# ESP32-P4 register map
Vendor: ESPRESSIF SYSTEMS (SHANGHAI) CO., LTD.; Series: ESP32 P-Series; File version: 3
CPU: RV32IMAFC r0p0, little endian, no MPU, FPU, 0 interrupt priority bits
Address unit: 32 bits
Registers are 32-bit, read-write, reset 0x0 unless marked. A register's access mark holds for its fields unless they carry their own. Offsets are from the block's base; [hi:lo] are bit positions; {n}, {i} and the like mark numbered series.

## PAU — PAU Peripheral
Base 0x60093000
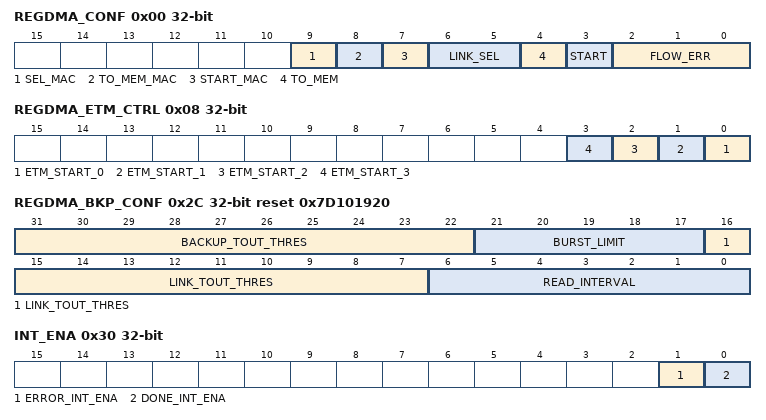
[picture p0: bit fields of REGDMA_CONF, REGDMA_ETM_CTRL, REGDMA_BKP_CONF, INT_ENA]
0x00 REGDMA_CONF access per field — Peri backup control register
  [9] SEL_MAC rw — mac hw/sw select
  [8] TO_MEM_MAC rw — mac sw backup direction(reg to mem / mem to reg)
  [7] START_MAC wo — mac sw backup start signal
  [6:5] LINK_SEL rw — Link select
  [4] TO_MEM rw — backup direction(reg to mem / mem to reg)
  [3] START wo — backup start signal
  [2:0] FLOW_ERR ro — backup error type
0x04 REGDMA_CLK_CONF — Clock control register
  [0] CLK_EN — clock enable
0x08 REGDMA_ETM_CTRL wo — ETM start ctrl reg
  [n] ETM_START_{n} (n=0..3) — etm_start_{n} reg
0x0C REGDMA_LINK_0_ADDR — link_0_addr
  [31:0] LINK_ADDR_0 — link_0_addr reg
{0xC+4i} REGDMA_LINK_{i}_ADDR (i=1..3) — Link_{i}_addr
  [31:0] LINK_ADDR_{i} — Link_{i}_addr reg
0x1C REGDMA_LINK_MAC_ADDR — Link_mac_addr
  [31:0] LINK_ADDR_MAC — Link_mac_addr reg
0x20 REGDMA_CURRENT_LINK_ADDR ro — current link addr
  [31:0] CURRENT_LINK_ADDR — current link addr reg
0x24 REGDMA_BACKUP_ADDR ro — Backup addr
  [31:0] BACKUP_ADDR — backup addr reg
0x28 REGDMA_MEM_ADDR ro — mem addr
  [31:0] MEM_ADDR — mem addr reg
0x2C REGDMA_BKP_CONF reset 0x7D101920 — backup config
  [31:22] BACKUP_TOUT_THRES — Backup timeout threshold
  [21:17] BURST_LIMIT
  [16:7] LINK_TOUT_THRES — link wait timeout threshold
  [6:0] READ_INTERVAL — Link read_interval
0x30 INT_ENA — Read only register for error and done
  [1] ERROR_INT_ENA — error flag
  [0] DONE_INT_ENA — backup done flag
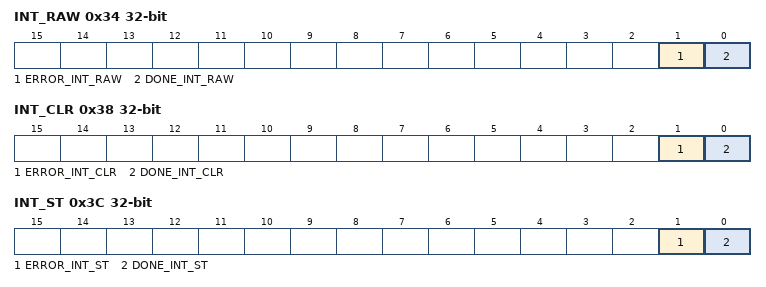
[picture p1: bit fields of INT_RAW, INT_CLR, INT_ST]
0x34 INT_RAW — Read only register for error and done
  [1] ERROR_INT_RAW — error flag
  [0] DONE_INT_RAW — backup done flag
0x38 INT_CLR wo — Read only register for error and done
  [1] ERROR_INT_CLR — error flag
  [0] DONE_INT_CLR — backup done flag
0x3C INT_ST ro — Read only register for error and done
  [1] ERROR_INT_ST — error flag
  [0] DONE_INT_ST — backup done flag
0x3FC DATE reset 0x2301310
  [27:0] DATE — REGDMA date information/ REGDMA version information.

## RSA — RSA (Rivest Shamir Adleman) Accelerator
Base 0x50092000
{0x0+i} M_MEM[{i}] (i=0..15) 8-bit access not given — Represents M
{0x200+i} Z_MEM[{i}] (i=0..15) 8-bit access not given — Represents Z
{0x400+i} Y_MEM[{i}] (i=0..15) 8-bit access not given — Represents Y
{0x600+i} X_MEM[{i}] (i=0..15) 8-bit access not given — Represents X
0x800 M_PRIME — Represents M'
0x804 MODE — Configures RSA length
  [6:0] MODE — Configures the RSA length.
0x808 QUERY_CLEAN ro — RSA initialization status
  [0] QUERY_CLEAN — Represents whether or not the RSA memory completes initialization.\\ 0: Not complete\\ 1: Completed\\
0x80C SET_START_MODEXP wo — Starts modular exponentiation
  [0] SET_START_MODEXP — Configures whether or not to starts the modular exponentiation. \\ 0: No effect\\ 1: Start\\
0x810 SET_START_MODMULT wo — Starts modular multiplication
  [0] SET_START_MODMULT — Configures whether or not to start the modular multiplication.\\ 0: No effect\\ 1: Start\\
0x814 SET_START_MULT wo — Starts multiplication
  [0] SET_START_MULT — Configures whether or not to start the multiplication.\\ 0: No effect\\ 1: Start\\
0x818 QUERY_IDLE ro — Represents the RSA status
  [0] QUERY_IDLE — Represents the RSA status.\\ 0: Busy\\ 1: Idle\\
0x81C INT_CLR wo — Clears RSA interrupt
  [0] CLEAR_INTERRUPT — Write 1 to clear the RSA interrupt.
0x820 CONSTANT_TIME reset 0x1 — Configures the constant_time option
  [0] CONSTANT_TIME — Configures the constant_time option. \\ 0: Acceleration\\ 1: No acceleration (default)\\
0x824 SEARCH_ENABLE — Configures the search option
  [0] SEARCH_ENABLE — Configures the search option. \\ 0: No acceleration (default)\\ 1: Acceleration\\ This option should be used together with RSA_SEARCH_POS_REG.
0x828 SEARCH_POS — Configures the search position
  [11:0] SEARCH_POS — Configures the starting address to start search. This field should be used together with RSA_SEARCH_ENABLE_REG. The field is only valid when RSA_SEARCH_ENABLE is high.
0x82C INT_ENA — Enables the RSA interrupt
  [0] INT_ENA — Write 1 to enable the RSA interrupt.
0x830 DATE reset 0x20200618 — Version control register
  [29:0] DATE — Version control register.
